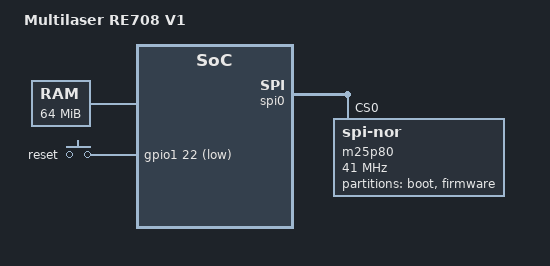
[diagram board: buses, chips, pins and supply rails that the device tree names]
// SPDX-License-Identifier: GPL-2.0
/dts-v1/;

#include "RTL8197F.dtsi"

#include <dt-bindings/gpio/gpio.h>
#include <dt-bindings/input/input.h>

/ {
	compatible = "multilaser,re708", "realtek,rtl8197f-soc";
	model = "Multilaser RE708 V1";

	memory {
		device_type = "memory";
		reg = <0x0 0x4000000>;
	};

	chosen {
		bootargs = "console=ttyS0,38400";
	};

	gpio-keys-polled {
		compatible = "gpio-keys-polled";
		#address-cells = <1>;
		#size-cells = <0>;
		poll-interval = <20>;

		reset {
			label = "reset";
			gpios = <&gpio1 22 GPIO_ACTIVE_LOW>;
			linux,code = <KEY_RESTART>;
		};
	};

	// Breaks device switch. Still needs fix before using it
	// gpio-leds {
	// 	compatible = "gpio-leds";

	// 	wps {
	// 		label = "re708:green:wps";
	// 		gpios = <&gpio1 25 GPIO_ACTIVE_LOW>;
	// 	};
	// };

};

&gpio1 {
	status = "okay";
};

&spi0 {
	status = "okay";

	m25p80@0 {
		#address-cells = <1>;
		#size-cells = <1>;
		compatible = "jedec,spi-nor";
		reg = <0>;
		spi-max-frequency = <41000000>;

		partition@0 {
			label = "boot";
			reg = <0x0 0x30000>;
			read-only;
		};

		partition@30000 {
			label = "firmware";
			reg = <0x30000 0x7C0000>;
		};
	};
};
